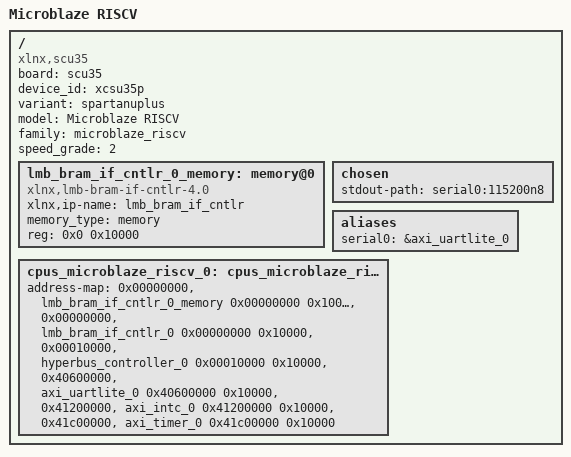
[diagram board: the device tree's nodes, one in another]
/dts-v1/;
#include "pl.dtsi"
/ {
	board = "scu35";
	compatible = "xlnx,scu35";
	device_id = "xcsu35p";
	#address-cells = <1>;
	variant = "spartanuplus";
	model = "Microblaze RISCV";
	#size-cells = <1>;
	family = "microblaze_riscv";
	speed_grade = "2";
	lmb_bram_if_cntlr_0_memory: memory@0 {
		compatible = "xlnx,lmb-bram-if-cntlr-4.0";
		xlnx,ip-name = "lmb_bram_if_cntlr";
		device_type = "memory";
		memory_type = "memory";
		reg = <0x0 0x10000>;
	};
	chosen {
		stdout-path = "serial0:115200n8";
	};
	aliases {
		serial0 = &axi_uartlite_0;
	};
	cpus_microblaze_riscv_0: cpus_microblaze_riscv@0 {
		address-map = <0x00000000 &lmb_bram_if_cntlr_0_memory 0x00000000 0x10000>, 
			      <0x00000000 &lmb_bram_if_cntlr_0 0x00000000 0x10000>, 
			      <0x00010000 &hyperbus_controller_0 0x00010000 0x10000>, 
			      <0x40600000 &axi_uartlite_0 0x40600000 0x10000>, 
			      <0x41200000 &axi_intc_0 0x41200000 0x10000>, 
			      <0x41c00000 &axi_timer_0 0x41c00000 0x10000>;
		#ranges-address-cells = <0x1>;
		#ranges-size-cells = <0x1>;
	};
};
